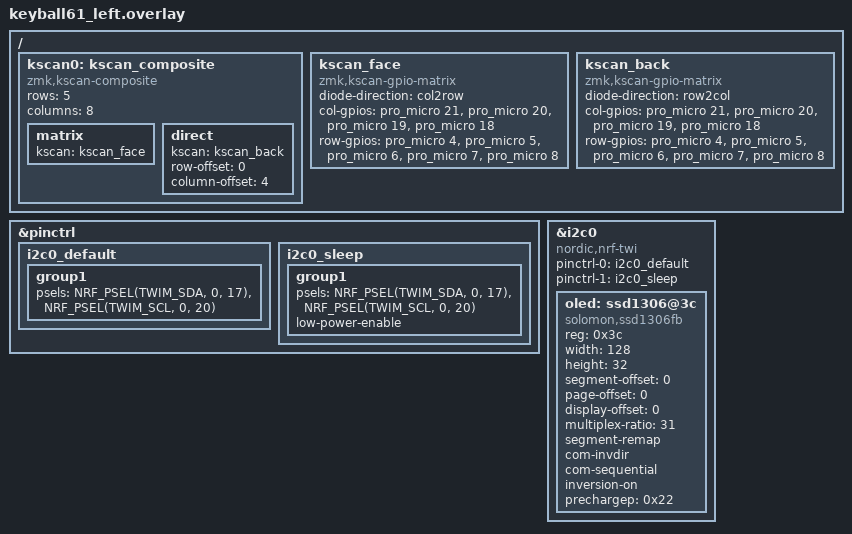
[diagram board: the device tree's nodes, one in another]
/*
 * Copyright (c) 2020 ZMK Contributors
 *
 * SPDX-License-Identifier: MIT
 */

#include "keyball61.dtsi"

/ {
    kscan0: kscan_composite {
        compatible = "zmk,kscan-composite";
        rows = <5>;
        columns = <8>;

        matrix {
            kscan = <&kscan_face>;
        };
        direct {
            kscan = <&kscan_back>;
            row-offset = <0>;
            column-offset = <4>;
        };
    };

    kscan_face: kscan_face {
        compatible = "zmk,kscan-gpio-matrix";
        diode-direction = "col2row";
        col-gpios
            = <&pro_micro 21 GPIO_ACTIVE_HIGH>
            , <&pro_micro 20 GPIO_ACTIVE_HIGH>
            , <&pro_micro 19 GPIO_ACTIVE_HIGH>
            , <&pro_micro 18 GPIO_ACTIVE_HIGH>
            ;
        row-gpios
            = <&pro_micro 4 (GPIO_ACTIVE_HIGH | GPIO_PULL_DOWN)>
            , <&pro_micro 5 (GPIO_ACTIVE_HIGH | GPIO_PULL_DOWN)>
            , <&pro_micro 6 (GPIO_ACTIVE_HIGH | GPIO_PULL_DOWN)>
            , <&pro_micro 7 (GPIO_ACTIVE_HIGH | GPIO_PULL_DOWN)>
            , <&pro_micro 8 (GPIO_ACTIVE_HIGH | GPIO_PULL_DOWN)>
            ;
    };

    kscan_back: kscan_back {
        compatible = "zmk,kscan-gpio-matrix";
        diode-direction = "row2col";
        col-gpios
            = <&pro_micro 21 (GPIO_ACTIVE_HIGH | GPIO_PULL_DOWN)>
            , <&pro_micro 20 (GPIO_ACTIVE_HIGH | GPIO_PULL_DOWN)>
            , <&pro_micro 19 (GPIO_ACTIVE_HIGH | GPIO_PULL_DOWN)>
            , <&pro_micro 18 (GPIO_ACTIVE_HIGH | GPIO_PULL_DOWN)>
            ;
        row-gpios
            = <&pro_micro 4 GPIO_ACTIVE_HIGH>
            , <&pro_micro 5 GPIO_ACTIVE_HIGH>
            , <&pro_micro 6 GPIO_ACTIVE_HIGH>
            , <&pro_micro 7 GPIO_ACTIVE_HIGH>
            , <&pro_micro 8 GPIO_ACTIVE_HIGH>
            ;
    };
};

&pinctrl {
    i2c0_default: i2c0_default {
        group1 {
            psels = <NRF_PSEL(TWIM_SDA, 0, 17)>,
                    <NRF_PSEL(TWIM_SCL, 0, 20)>;
        };
    };

    i2c0_sleep: i2c0_sleep {
        group1 {
            psels = <NRF_PSEL(TWIM_SDA, 0, 17)>,
                    <NRF_PSEL(TWIM_SCL, 0, 20)>;
            low-power-enable;
        };
    };
};

&i2c0 {
    status = "okay";
    compatible = "nordic,nrf-twi";
    pinctrl-0 = <&i2c0_default>;
    pinctrl-1 = <&i2c0_sleep>;
    pinctrl-names = "default", "sleep";

    oled: ssd1306@3c {
        compatible = "solomon,ssd1306fb";
        reg = <0x3c>;
        width = <128>;
        height = <32>;
        segment-offset = <0>;
        page-offset = <0>;
        display-offset = <0>;
        multiplex-ratio = <31>;
        segment-remap;
        com-invdir;
        com-sequential;
        inversion-on;
        prechargep = <0x22>;
    };
};
